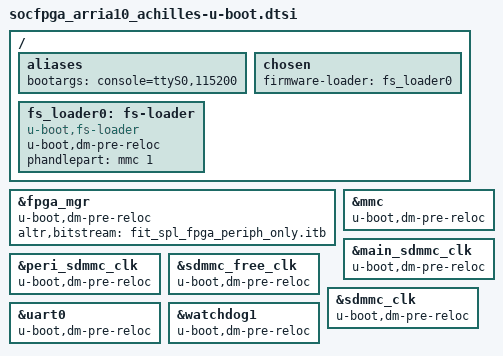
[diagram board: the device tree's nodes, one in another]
/*
 * Copyright (C) 2021 REFLEX CES <www.reflexces.com>
 *
 * This program is free software; you can redistribute it and/or modify
 * it under the terms of the GNU General Public License as published by
 * the Free Software Foundation; either version 2 of the License, or
 * (at your option) any later version.
 *
 * This program is distributed in the hope that it will be useful,
 * but WITHOUT ANY WARRANTY; without even the implied warranty of
 * MERCHANTABILITY or FITNESS FOR A PARTICULAR PURPOSE.  See the
 * GNU General Public License for more details.
 *
 * You should have received a copy of the GNU General Public License
 * along with this program.  If not, see <http://www.gnu.org/licenses/>.
 */

#include "socfpga_arria10_achilles_handoff.h"
#include "socfpga_arria10-handoff.dtsi"
#include "socfpga_arria10_handoff_u-boot.dtsi"
#include "socfpga_arria10-u-boot.dtsi"

/ {
	aliases {
		bootargs = "console=ttyS0,115200";
	};

	chosen {
		firmware-loader = <&fs_loader0>;
	};

	fs_loader0: fs-loader {
		u-boot,dm-pre-reloc;
		compatible = "u-boot,fs-loader";
		phandlepart = <&mmc 1>;
	};
};

&fpga_mgr {
	u-boot,dm-pre-reloc;
	altr,bitstream = "fit_spl_fpga_periph_only.itb";
};

&mmc {
	u-boot,dm-pre-reloc;
};

/* Clock available early */
&main_sdmmc_clk {
	u-boot,dm-pre-reloc;
};

&peri_sdmmc_clk {
	u-boot,dm-pre-reloc;
};

&sdmmc_free_clk {
	u-boot,dm-pre-reloc;
};

&sdmmc_clk {
	u-boot,dm-pre-reloc;
};

&uart0 {
	u-boot,dm-pre-reloc;
};

&watchdog1 {
	u-boot,dm-pre-reloc;
};
